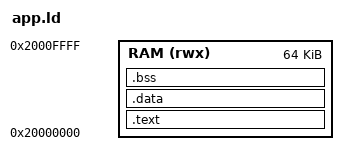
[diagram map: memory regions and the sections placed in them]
ENTRY(_start)

MEMORY
{
  RAM (rwx) : ORIGIN = 0x20000000, LENGTH = 64K
}

SECTIONS
{
  .text : {
    KEEP(*(.text.start))
    *(.text*)
    *(.rodata*)
  } > RAM

  .data : {
    *(.data*)
  } > RAM

  .bss (NOLOAD) : {
    _sbss = .;
    *(.bss*)
    *(COMMON)
    _ebss = .;
  } > RAM

  _stack_top = ORIGIN(RAM) + LENGTH(RAM);
}
